# S1C31D01 register map
Vendor: Epson; Series: S1C31D01; File version: 1.00
ARM 32-bit Cortex-M0 plus Microcontroller based device, CPU clock up to 21.7MHz
CPU: CM0PLUS r0p1, little endian, MPU, no FPU, VTOR, 2 interrupt priority bits
Registers are 16-bit, read-write, reset 0x0 unless marked. A register's access mark holds for its fields unless they carry their own. Offsets are from the block's base; lines under a group give offsets from that group; [hi:lo] are bit positions; {n}, {i} and the like mark numbered series; 'fields as' and 'values as' point back to an identical list; <NAME> marks a mode.

## Memory map
0x20400000 USB size 0x105 — USB Controller
0x40000000 SYS size 0x2 — System register
0x40000020 PWGA size 0x2 — Operation mode and voltage control
0x40000040 CLG size 0x16 — Clock sources control and clock supply management
0x40000080 CACHE size 0x2 — Cache controller
0x400000A0 WDT2 size 0x6 — Watchdog 2 timer counter, clock source and clock division ratio control
0x400000C0 RTCA size 0x14 — Real-time clock control
0x40000100 SVD3 size 0x8 — Supply voltage detector control
0x40000160 T16_0 size 0xE — 16 Timer / Counter, counting up or down from different sources
0x400001B0 FLASHC size 0x2 — Flash controller
0x40000200 PPORT size 0xE4 — I/O Ports control
0x40000300 UPMUX size 0x20 — Universal port multiplexer control
0x40000380 UART3_0 size 0x16 — UART3 channel 0 control
0x400003A0 T16_1 size 0xE
0x400003B0 SPIA_0 size 0x10 — Synchronous serial interface control
0x400003C0 I2C_0 size 0x18 — I2C channel 0 control
0x40000400 T16B_0 size 0x3E — 16-bit PWM timer channel 0 comparator/capture control
0x40000440 T16B_1 size 0x3E — 16-bit PWM timer channel 1 comparator/capture control
0x40000480 T16_3 size 0xE
0x400004A0 T16_4 size 0xE
0x400004C0 T16_5 size 0xE
0x40000600 UART3_1 size 0x16 — UART3 channel 1 control
0x40000620 UART3_2 size 0x16 — UART3 channel 2 control
0x40000660 T16_6 size 0xE
0x40000670 SPIA_1 size 0x10 — Synchronous serial interface control
0x40000680 T16_2 size 0xE
0x40000690 QSPI_0 size 0x1A — Quad Synchronous Serial Interface channel 0
0x400006C0 I2C_1 size 0x18 — I2C channel 1 control
0x40000700 SNDA size 0xE — SNDA Sound generatior
0x40000720 REMC3 size 0x14 — IR Remote Controller
0x40000780 T16_7 size 0xE
0x400007A0 ADC12A_0 size 0x1E — 12 bit ADC controller
0x400007C0 TSRVR_0 size 0x4 — Temparature sensor control
0x40000970 USBMISC size 0x8 — USB miscellaneous configuration register
0x40001000 DMAC size 0x1018 — PrimeCell uDMA Controller
0x40003000 MDC size 0xE2 — Memory display controller

## Interrupts
0 DMAC
1 SVD3
2 PORT (PPORT)
3 CLG
4 RTC (RTCA)
5 T16_0
6 UART3_0
7 T16_1
8 SPIA_0
9 I2C_0
10 T16B_0
11 T16B_1
12 UART3_1
13 T16_2
14 QSPI_0
15 I2C_1
16 REMC3
17 UART3_2
18 T16_3
19 USB
20 SPIA_1
21 SNDA
22 T16_4
23 T16_5
24 T16_6
25 T16_7
26 MDC
27 ADC12A_0

## SYS — System register
Base 0x40000000
0x00 PROT — Register Write Protect Register
  [15:0] PROT — Register write protect

## PWGA — Operation mode and voltage control
Base 0x40000020
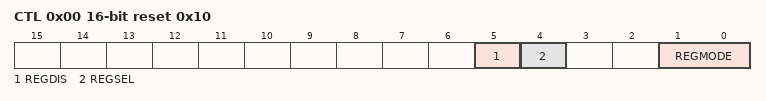
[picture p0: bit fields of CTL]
0x00 CTL reset 0x10 — Control Register
  [5] REGDIS — Regulator discharge enable (can be write protected)
    0=NORMAL (Normal operation); 1=DISCHARGE (Regulator discharge)
  [4] REGSEL — Regulator voltage select (can be write protected)
    0=1_2V; 1=1_8V
  [1:0] REGMODE — Regulator operation mode select (can be write protected)
    0=AUTO (Automatic mode); 2=NORM (Normal mode); 3=ECON (Economy mode)

## DMAC — PrimeCell uDMA Controller
Base 0x40001000
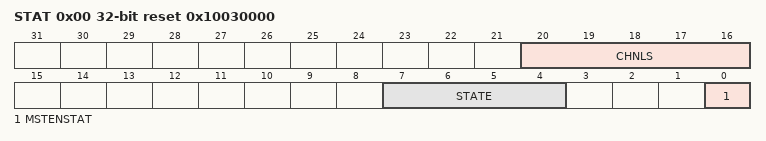
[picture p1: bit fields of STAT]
0x00 STAT 32-bit ro reset 0x10030000 — Returns the DMAC status
  [20:16] CHNLS — Number of available DMAC channels minus one
  [7:4] STATE — These bits indicates the DMA transfer status
  [0] MSTENSTAT — This bit indicates the DMA controller status
0x04 CFG 32-bit — DMA configuration
  [0] MSTEN wo — This bit enables the DMA controller.
0x08 CPTR 32-bit — Pointer to the base address of the primary data structure
  [31:0] CPTR — DMAC Control Data Base Pointer Reg
0x0C ACPTR 32-bit ro — Pointer to the base address of the alternative data structure
  [31:0] ACPTR — These bits show the alternate data structure base address
0x14 SWREQ 32-bit wo — The write-only register enables you to generate a software DMA request
  [3:0] SWREQ — These bits issue a software DMA transfer request to each channel
0x20 RMSET 32-bit — Setting this bit to 1 causes the DMA channel to no longer respond to data requests from peripherals. The channel will always respond to software transfer requests
  [3:0] RMSET
0x24 RMCLR 32-bit wo — Firmware can write a 1 to the register to clear the mask for a channel
  [3:0] RMCLR
0x28 ENSET 32-bit — These bits enable each DMAC channel. Returns the enable status of the channels
  [3:0] ENSET
0x2C ENCLR 32-bit wo — Set the appropriate bit to disable the corresponding DMA channel
  [3:0] ENCLR
0x30 PASET 32-bit — These bits enable the alternate data structures. Returns status of alternate structures.
  [3:0] PASET
0x34 PACLR 32-bit wo — These bits disable the alternate data structures
  [3:0] PACLR
0x38 PRSET 32-bit — These bits increase the priority of each channel
  [3:0] PRSET
0x3C PRCLR 32-bit wo — These bits decrease the priority of each channel
  [3:0] PRCLR
0x4C ERRIF 32-bit — DMAC Error Interrupt Flag Register
  [0] ERRIF — Returns the status of DMAC error. Cleared by writing 1
0x1000 ENDIF 32-bit — DMAC Transfer Completion Interrupt Flag Register
  [3:0] ENDIF
0x1008 ENDIESET 32-bit — DMAC Transfer Completion Interrupt Enable Set Register
  [3:0] ENDIESET
0x100C ENDIECLR 32-bit wo — DMAC Transfer Completion Interrupt Enable Clear Register
  [3:0] ENDIECLR
0x1010 ERRIESET 32-bit — DMAC Error Interrupt Enable Set Register
  [0] ERRIESET
0x1014 ERRIECLR 32-bit wo — DMAC Error Interrupt Enable Clear Register
  [0] ERRIECLR

## Licence text in the file
Copyright (C) SEIKO EPSON CORPORATION 2016. All rights reserved.
